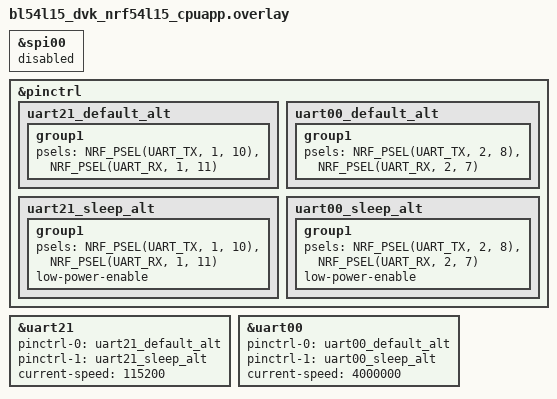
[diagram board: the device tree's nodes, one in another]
/*
 * Copyright (c) 2024 Nordic Semiconductor ASA
 * Copyright (c) 2025 Ezurio LLC
 *
 * SPDX-License-Identifier: Apache-2.0
 */

&spi00 {
	status = "disabled";
};

&pinctrl {
	uart21_default_alt: uart21_default_alt {
		group1 {
			psels = <NRF_PSEL(UART_TX, 1, 10)>,
				<NRF_PSEL(UART_RX, 1, 11)>;
		};
	};

	uart21_sleep_alt: uart21_sleep_alt {
		group1 {
			psels = <NRF_PSEL(UART_TX, 1, 10)>,
				<NRF_PSEL(UART_RX, 1, 11)>;
			low-power-enable;
		};
	};

	uart00_default_alt: uart00_default_alt {
		group1 {
			psels = <NRF_PSEL(UART_TX, 2, 8)>,
				<NRF_PSEL(UART_RX, 2, 7)>;
		};
	};

	uart00_sleep_alt: uart00_sleep_alt {
		group1 {
			psels = <NRF_PSEL(UART_TX, 2, 8)>,
				<NRF_PSEL(UART_RX, 2, 7)>;
			low-power-enable;
		};
	};
};

dut: &uart21 {
	status = "okay";
	pinctrl-0 = <&uart21_default_alt>;
	pinctrl-1 = <&uart21_sleep_alt>;
	pinctrl-names = "default", "sleep";
	current-speed = <115200>;
};

dut2: &uart00 {
	status = "okay";
	pinctrl-0 = <&uart00_default_alt>;
	pinctrl-1 = <&uart00_sleep_alt>;
	pinctrl-names = "default", "sleep";
	current-speed = <4000000>;
};
